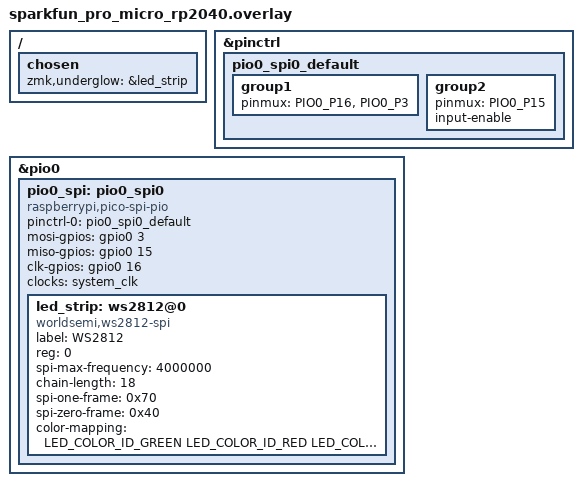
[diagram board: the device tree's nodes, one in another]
#include <dt-bindings/led/led.h>

&pinctrl {
    pio0_spi0_default: pio0_spi0_default {
        group1 {
            pinmux = <PIO0_P16>, <PIO0_P3>;
        };
        group2 {
            pinmux = <PIO0_P15>;
            input-enable;
        };
    };
};

&pio0 {
    status = "okay";

    pio0_spi: pio0_spi0 {
        pinctrl-0 = <&pio0_spi0_default>;
        pinctrl-names = "default";

        compatible = "raspberrypi,pico-spi-pio";

        #address-cells = <1>;
        #size-cells = <0>;

        mosi-gpios = <&gpio0 3 GPIO_ACTIVE_HIGH>;
        miso-gpios = <&gpio0 15 0>;
        clk-gpios = <&gpio0 16 GPIO_ACTIVE_HIGH>;

        clocks = <&system_clk>;

        led_strip: ws2812@0 {
            compatible = "worldsemi,ws2812-spi";
            label = "WS2812";

            // spi
            reg = <0>;
            spi-max-frequency = <4000000>;

            // ws2812
            chain-length = <18>;
            spi-one-frame = <0x70>;
            spi-zero-frame = <0x40>;
            color-mapping = <LED_COLOR_ID_GREEN LED_COLOR_ID_RED LED_COLOR_ID_BLUE>;
        };
    };
};

/ {
    chosen {
        zmk,underglow = &led_strip;
    };
};
